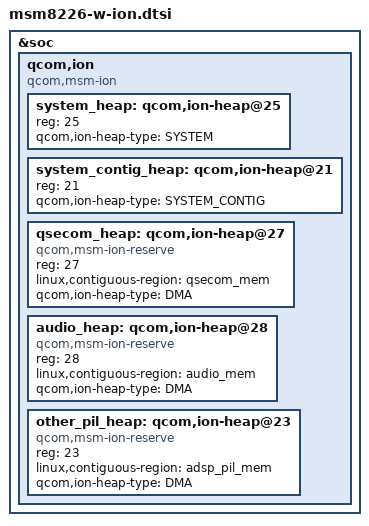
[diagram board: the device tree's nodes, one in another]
/* Copyright (c) 2014, The Linux Foundation. All rights reserved.
 *
 * This program is free software; you can redistribute it and/or modify
 * it under the terms of the GNU General Public License version 2 and
 * only version 2 as published by the Free Software Foundation.
 *
 * This program is distributed in the hope that it will be useful,
 * but WITHOUT ANY WARRANTY; without even the implied warranty of
 * MERCHANTABILITY or FITNESS FOR A PARTICULAR PURPOSE.  See the
 * GNU General Public License for more details.
 */

&soc {
	qcom,ion {
		compatible = "qcom,msm-ion";
		#address-cells = <1>;
		#size-cells = <0>;

		system_heap: qcom,ion-heap@25 {
			reg = <25>;
			qcom,ion-heap-type = "SYSTEM";
		};

		system_contig_heap: qcom,ion-heap@21 {
			reg = <21>;
			qcom,ion-heap-type = "SYSTEM_CONTIG";
		};

		qsecom_heap: qcom,ion-heap@27 { /* QSECOM HEAP */
			compatible = "qcom,msm-ion-reserve";
			reg = <27>;
			linux,contiguous-region = <&qsecom_mem>;
			qcom,ion-heap-type = "DMA";
		};

		audio_heap: qcom,ion-heap@28 { /* AUDIO HEAP */
			compatible = "qcom,msm-ion-reserve";
			reg = <28>;
			linux,contiguous-region = <&audio_mem>;
			qcom,ion-heap-type = "DMA";
		};

		other_pil_heap: qcom,ion-heap@23 { /* OTHER PIL HEAP */
			compatible = "qcom,msm-ion-reserve";
			reg = <23>;
			linux,contiguous-region = <&adsp_pil_mem>;
			qcom,ion-heap-type = "DMA";
		};

	};
};
